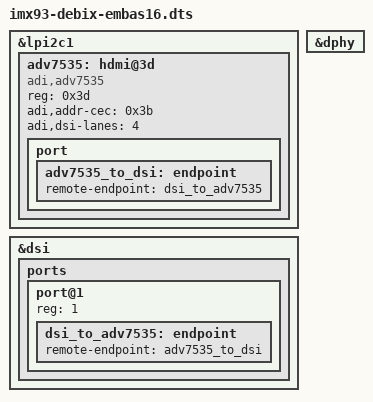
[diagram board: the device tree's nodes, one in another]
// SPDX-License-Identifier: (GPL-2.0+ OR MIT)
/*
 * Copyright 2022 NXP
 */

#include "imx93-11x11-evk.dts"

/ {

};

&lpi2c1 {
	adv7535: hdmi@3d {
		compatible = "adi,adv7535";
		reg = <0x3d>;
		adi,addr-cec = <0x3b>;
		adi,dsi-lanes = <4>;
		status = "okay";

		port {
			adv7535_to_dsi: endpoint {
				remote-endpoint = <&dsi_to_adv7535>;
			};
		};
	};
};

&dphy {
	status = "okay";
};

&dsi {
	status = "okay";
	ports {
		port@1 {
			reg = <1>;

			dsi_to_adv7535: endpoint {
				remote-endpoint = <&adv7535_to_dsi>;
			};
		};
	};
};

